# CS32F031x register map
File version: 1.0
Registers are 32-bit, read-write, reset 0x0 unless marked. A register's access mark holds for its fields unless they carry their own. Offsets are from the block's base; [hi:lo] are bit positions; {n}, {i} and the like mark numbered series.

## TIM2 — General-purpose-timers
Base 0x40000000
Same registers: TIM3 0x40000400
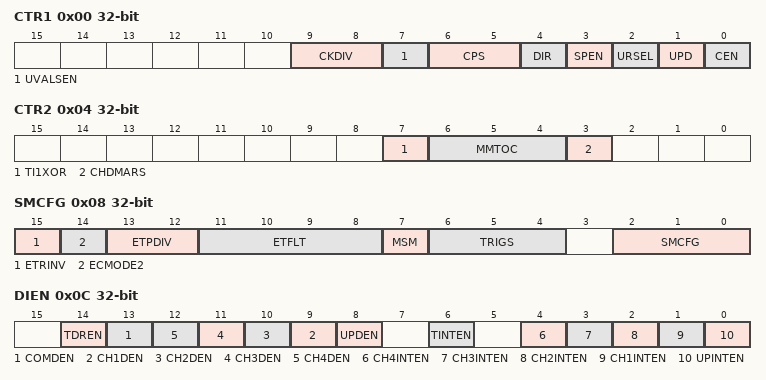
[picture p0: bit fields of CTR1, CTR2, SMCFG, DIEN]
0x00 CTR1 — control register 1
  [9:8] CKDIV — Clock division
  [7] UVALSEN — UVAL shadow enable
  [6:5] CPS — Count pattern selection
  [4] DIR — Direction
  [3] SPEN — Single pulse enable
  [2] URSEL — Update request selection
  [1] UPD — Update disable
  [0] CEN — Counter enable
0x04 CTR2 — control register 2
  [7] TI1XOR — XOR input for TI1
  [6:4] MMTOC — Master mode trigger out control
  [3] CHDMARS — DMA request source of channel
0x08 SMCFG — slave mode configuration register
  [15] ETRINV — ETR invert
  [14] ECMODE2 — External clock mode 2 enable
  [13:12] ETPDIV — External trigger pre-divide
  [11:8] ETFLT — External trigger filter
  [7] MSM — Master/Slave mode
  [6:4] TRIGS — Trigger selection
  [2:0] SMCFG — Slave mode configuration
0x0C DIEN — DMA and interrupt enable register
  [14] TDREN — Enable bit for trigger DMA request
  [13] COMDEN — Enable bit for COM event DMA request
  [n+8] CH{n}DEN (n=1..4) — Enable bit for channel {n} DMA request
  [8] UPDEN — Enable bit for update DMA request
  [6] TINTEN — Enable bit for trigger interrupt
  [4] CH4INTEN — Channel 4 capture compare interrupt flag
  [3] CH3INTEN — Channel 3 capture compare interrupt flag
  [2] CH2INTEN — Channel2 capture compare interrupt flag
  [1] CH1INTEN — Channel1 capture compare interrupt flag
  [0] UPINTEN — Enable bit for update interrupt
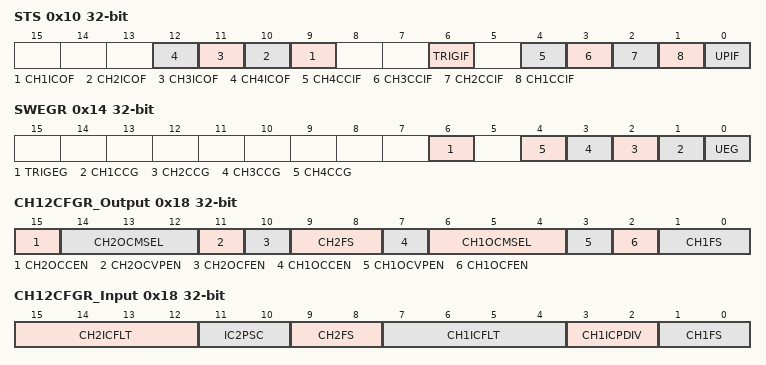
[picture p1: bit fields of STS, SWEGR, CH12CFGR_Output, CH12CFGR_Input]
0x10 STS — status register
  [n+8] CH{n}ICOF (n=1..4) — Channel {n} input capture overflow
  [6] TRIGIF — Interrupt flag of trigger
  [4] CH4CCIF — Channel 4 capture compare interrupt flag
  [3] CH3CCIF — Channel 3 capture compare interrupt flag
  [2] CH2CCIF — Channel2 capture compare interrupt flag
  [1] CH1CCIF — Channel1 capture compare interrupt flag
  [0] UPIF — Enable bit for update interrupt
0x14 SWEGR wo — software event generation register
  [6] TRIGEG — Trigger event generation
  [n] CH{n}CCG (n=1..4) — Channel 1 capture compare event generation
  [0] UEG — Update event generation
0x18 CH12CFGR_Output — channel 1 and channel 2 configuration register(output mode)
  [15] CH2OCCEN — Channel 2 output compare clear enable
  [14:12] CH2OCMSEL — Channel 2 output compare mode selection
  [11] CH2OCVPEN — Channel 2 output compare value preload enable
  [10] CH2OCFEN — Channel 2 output compare fast enable
  [9:8] CH2FS — Channel 2 function selection
  [7] CH1OCCEN — Channel 1 output compare clear enable
  [6:4] CH1OCMSEL — Channel 1 output compare mode selection
  [3] CH1OCVPEN — Channel 1 output compare value preload enable
  [2] CH1OCFEN — Channel 1 output compare fast enable
  [1:0] CH1FS — Channel 1 function selection
0x18 CH12CFGR_Input (alternate view of CH12CFGR_Output) — channel 1 and channel 2 configuration register (input mode)
  [15:12] CH2ICFLT — Channel 2 input capture filter
  [11:10] IC2PSC — Channel 2 input capture pre-divide
  [9:8] CH2FS — Channel 2 function selection
  [7:4] CH1ICFLT — Channel 1 input capture filter
  [3:2] CH1ICPDIV — Channel 1 input capture pre-divide
  [1:0] CH1FS — Channel 1 function selection
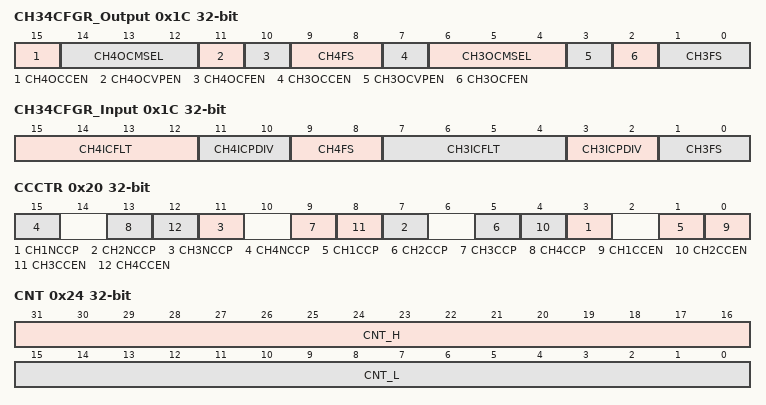
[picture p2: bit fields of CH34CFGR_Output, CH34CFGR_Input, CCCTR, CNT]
0x1C CH34CFGR_Output — channel 3 and channel 4 configuration register (output mode)
  [15] CH4OCCEN — Channel 4 output compare clear enable
  [14:12] CH4OCMSEL — Channel 4 output compare mode selection
  [11] CH4OCVPEN — Channel 4 output compare value preload enable
  [10] CH4OCFEN — Channel 4 output compare fast enable
  [9:8] CH4FS — Channel 4 function selection
  [7] CH3OCCEN — Channel 3 output compare clear enable
  [6:4] CH3OCMSEL — Channel 3 output compare mode selection
  [3] CH3OCVPEN — Channel 3 output compare value preload enable
  [2] CH3OCFEN — Channel 3 output compare fast enable
  [1:0] CH3FS — Channel 3 function selection
0x1C CH34CFGR_Input (alternate view of CH34CFGR_Output) — channel 3 and channel 4 configuration register (input mode)
  [15:12] CH4ICFLT — Channel 4 input capture filter
  [11:10] CH4ICPDIV — Channel 4 input capture pre-divide
  [9:8] CH4FS — Channel 4 function selection
  [7:4] CH3ICFLT — Channel 3 input capture filter
  [3:2] CH3ICPDIV — Channel 3 input capture pre-divide
  [1:0] CH3FS — Channel 3 function selection
0x20 CCCTR — channel capture compare control register
  [4n-1] CH{n}NCCP (n=1..4) — Channel {n} complementary capture compare Polarity
  [4n-3] CH{n}CCP (n=1..4) — Channel {n} capture compare Polarity
  [4n-4] CH{n}CCEN (n=1..4) — Channel {n} capture compare enable
0x24 CNT — counter
  [31:16] CNT_H — High counter value (TIM2 only)
  [15:0] CNT_L — Low counter value
0x28 PDIV — pre-divider
  [15:0] PDIV — pre-divider value
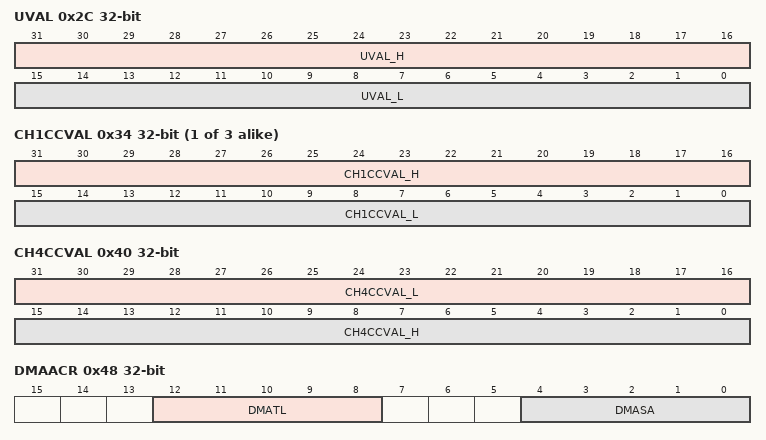
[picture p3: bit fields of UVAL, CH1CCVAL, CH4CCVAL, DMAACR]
0x2C UVAL — counter update register
  [31:16] UVAL_H — High Counter update value (TIM2 only)
  [15:0] UVAL_L — Low Counter update value
{0x30+4i} CH{i}CCVAL (i=1..3) — channel {i} capture compare value register
  [31:16] CH{i}CCVAL_H — Channel {i} high capture compare value (TIM2 only)
  [15:0] CH{i}CCVAL_L — Channel {i} low capture compare value
0x40 CH4CCVAL — channel 4 capture compare value register
  [31:16] CH4CCVAL_L — Channel 4 high capture compare value (TIM2 only)
  [15:0] CH4CCVAL_H — Channel 4 low capture compare value
0x48 DMAACR — DMA access configuration register
  [12:8] DMATL — DMA transfer length
  [4:0] DMASA — DMA start address
0x4C DMAIR — DMA access interface register
  [15:0] DMAI — DMA access interface
